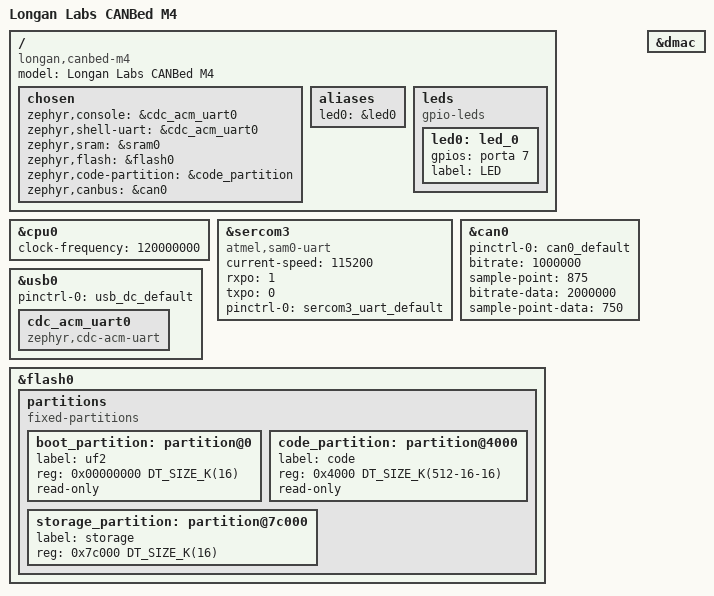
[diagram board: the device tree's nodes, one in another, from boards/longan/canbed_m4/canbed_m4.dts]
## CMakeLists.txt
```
# SPDX-License-Identifier: Apache-2.0
cmake_minimum_required(VERSION 3.20.0)

# The CMSIS device header for the ATSAME51G19A is not shipped by hal_atmel;
# soc.h (patched, see zephyr/patches/) includes <same51g19a.h> from here.
list(APPEND BOARD_ROOT ${CMAKE_CURRENT_SOURCE_DIR})

find_package(Zephyr REQUIRED HINTS $ENV{ZEPHYR_BASE})
project(canbed_m4_can_loopback)

zephyr_include_directories(include)

target_sources(app PRIVATE
  src/main.c
  src/dm/dm_motor.c
  src/dm/dm_motor_pack.c
  src/dm/dm_shell.c
)
target_include_directories(app PRIVATE src/dm)

# Keeps big app buffers behind the CAN message RAM (see the file).
zephyr_linker_sources(NOINIT linker/dm_trace.ld)
```

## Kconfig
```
# SPDX-License-Identifier: Apache-2.0

module = DM_MOTOR
module-str = dm_motor
source "subsys/logging/Kconfig.template.log_config"

source "Kconfig.zephyr"
```

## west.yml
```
# West manifest: Zephyr 4.4 plus only the modules this board needs.
manifest:
  remotes:
    - name: zephyrproject-rtos
      url-base: https://github.com/zephyrproject-rtos
  projects:
    - name: zephyr
      remote: zephyrproject-rtos
      revision: v4.4.0
      import:
        name-allowlist:
          - cmsis
          - cmsis_6
          - hal_atmel
  self:
    path: app
```

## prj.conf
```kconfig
CONFIG_CAN=y
CONFIG_CAN_FD_MODE=y
CONFIG_CAN_LOG_LEVEL_INF=y

CONFIG_LOG=y
CONFIG_LOG_MODE_IMMEDIATE=y
CONFIG_PRINTK=y

CONFIG_SHELL=y
CONFIG_CAN_SHELL=y
CONFIG_DEVICE_SHELL=y
CONFIG_KERNEL_SHELL=y

CONFIG_MAIN_STACK_SIZE=2048

# Shell needs float printing and a bit more stack for the dm commands.
CONFIG_CBPRINTF_FP_SUPPORT=y
CONFIG_SHELL_STACK_SIZE=3072
CONFIG_DM_MOTOR_LOG_LEVEL_INF=y

# strtof for the shell commands (minimal libc lacks it)
CONFIG_NEWLIB_LIBC=y
CONFIG_NEWLIB_LIBC_NANO=y

# The motor loops run on the system work queue at 1 kHz; printk with floats needs room.
CONFIG_SYSTEM_WORKQUEUE_STACK_SIZE=2048
```

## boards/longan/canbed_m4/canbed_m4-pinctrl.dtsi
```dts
/*
 * Pin multiplexing for the Longan Labs CANBed M4 (ATSAME51G19A, QFN48).
 * SPDX-License-Identifier: Apache-2.0
 */

#include <dt-bindings/pinctrl/same51g-pinctrl.h>

&pinctrl {
	/* Serial1 on the Grove connector / 2x9 header: PA17 TX, PA16 RX */
	sercom3_uart_default: sercom3_uart_default {
		group1 {
			pinmux = <PA17D_SERCOM3_PAD0>,
				 <PA16D_SERCOM3_PAD1>;
		};
	};

	/* I2C on the Grove connector: PA12 SDA, PA13 SCL */
	sercom2_i2c_default: sercom2_i2c_default {
		group1 {
			pinmux = <PA12C_SERCOM2_PAD0>,
				 <PA13C_SERCOM2_PAD1>;
		};
	};

	/* SPI header J8: PA00 MOSI, PA01 SCK, PB23 MISO */
	sercom1_spi_default: sercom1_spi_default {
		group1 {
			pinmux = <PA0D_SERCOM1_PAD0>,
				 <PA1D_SERCOM1_PAD1>,
				 <PB23C_SERCOM1_PAD3>;
		};
	};

	/* CAN0 to the MCP2542FD transceiver (STBY tied low) */
	can0_default: can0_default {
		group1 {
			pinmux = <PA22I_CAN0_TX>,
				 <PA23I_CAN0_RX>;
		};
	};

	usb_dc_default: usb_dc_default {
		group1 {
			pinmux = <PA25H_USB_DP>,
				 <PA24H_USB_DM>;
		};
	};
};
```

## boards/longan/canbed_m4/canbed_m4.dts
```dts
/*
 * Longan Labs CANBed M4: ATSAME51G19A (Cortex-M4F, 512 KiB flash, 192 KiB RAM)
 * with an MCP2542FD CAN FD transceiver, USB, and a 16 KiB UF2 bootloader.
 *
 * SPDX-License-Identifier: Apache-2.0
 */

/dts-v1/;
#include <atmel/same5xx19.dtsi>
#include <zephyr/dt-bindings/gpio/gpio.h>
#include "canbed_m4-pinctrl.dtsi"

/ {
	model = "Longan Labs CANBed M4";
	compatible = "longan,canbed-m4";

	chosen {
		zephyr,console = &cdc_acm_uart0;
		zephyr,shell-uart = &cdc_acm_uart0;
		zephyr,sram = &sram0;
		zephyr,flash = &flash0;
		zephyr,code-partition = &code_partition;
		zephyr,canbus = &can0;
	};

	aliases {
		led0 = &led0;
	};

	leds {
		compatible = "gpio-leds";

		/* D5, blue, active high (Arduino D13) */
		led0: led_0 {
			gpios = <&porta 7 GPIO_ACTIVE_HIGH>;
			label = "LED";
		};
	};
};

&cpu0 {
	clock-frequency = <120000000>;
};

/* Serial1 (Grove J11 / header J12) */
&sercom3 {
	status = "okay";
	compatible = "atmel,sam0-uart";
	current-speed = <115200>;
	rxpo = <1>;
	txpo = <0>;
	pinctrl-0 = <&sercom3_uart_default>;
	pinctrl-names = "default";
};

&can0 {
	status = "okay";
	pinctrl-0 = <&can0_default>;
	pinctrl-names = "default";
	bitrate = <1000000>;
	sample-point = <875>;
	bitrate-data = <2000000>;
	sample-point-data = <750>;
};

zephyr_udc0: &usb0 {
	status = "okay";
	pinctrl-0 = <&usb_dc_default>;
	pinctrl-names = "default";

	cdc_acm_uart0: cdc_acm_uart0 {
		compatible = "zephyr,cdc-acm-uart";
	};
};

&dmac {
	status = "okay";
};

&flash0 {
	partitions {
		compatible = "fixed-partitions";
		#address-cells = <1>;
		#size-cells = <1>;

		boot_partition: partition@0 {
			label = "uf2";
			reg = <0x00000000 DT_SIZE_K(16)>;
			read-only;
		};

		code_partition: partition@4000 {
			label = "code";
			reg = <0x4000 DT_SIZE_K(512-16-16)>;
			read-only;
		};

		/* last 16 KiB free for NVS/LittleFS if wanted */
		storage_partition: partition@7c000 {
			label = "storage";
			reg = <0x7c000 DT_SIZE_K(16)>;
		};
	};
};
```

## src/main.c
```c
/*
 * CANBed M4 CAN loopback self-test.
 *
 * Puts CAN0 into internal loopback (frames are transmitted and received by the
 * same controller without reaching the bus pins), sends a classic
 * frame and a 64-byte CAN FD frame with bit-rate switching, and checks that
 * both come back intact.  Results go to the USB CDC console, where the
 * Zephyr shell (`can ...` commands) stays available afterwards.
 *
 * SPDX-License-Identifier: Apache-2.0
 */

#include <string.h>

#include <zephyr/device.h>
#include <zephyr/drivers/can.h>
#include <zephyr/drivers/gpio.h>
#include <zephyr/drivers/uart.h>
#include <zephyr/shell/shell.h>
#include <zephyr/kernel.h>
#include <zephyr/logging/log.h>
#include <zephyr/version.h>
#include <zephyr/sys/byteorder.h>

#include "dm_motor.h"

LOG_MODULE_REGISTER(loopback, LOG_LEVEL_INF);

static const struct device *const can_dev = DEVICE_DT_GET(DT_CHOSEN(zephyr_canbus));
static const struct gpio_dt_spec led = GPIO_DT_SPEC_GET(DT_ALIAS(led0), gpios);

CAN_MSGQ_DEFINE(rx_msgq, 8);

#define TEST_ID_CLASSIC 0x123
#define TEST_ID_FD      0x1ABCDEF

static int add_filters(void)
{
	const struct can_filter classic = {
		.id = TEST_ID_CLASSIC,
		.mask = CAN_STD_ID_MASK,
		.flags = 0,
	};
	const struct can_filter fd = {
		.id = TEST_ID_FD,
		.mask = CAN_EXT_ID_MASK,
		.flags = CAN_FILTER_IDE,
	};
	int ret;

	ret = can_add_rx_filter_msgq(can_dev, &rx_msgq, &classic);
	if (ret < 0) {
		LOG_ERR("standard filter: %d", ret);
		return ret;
	}
	ret = can_add_rx_filter_msgq(can_dev, &rx_msgq, &fd);
	if (ret < 0) {
		LOG_ERR("extended filter: %d", ret);
		return ret;
	}
	return 0;
}

static void tx_done(const struct device *dev, int error, void *user_data)
{
	if (error != 0) {
		LOG_ERR("tx callback error %d", error);
	}
}

/* Send one frame and wait for it to come back through the loopback. */
static int roundtrip(const struct can_frame *tx, const char *name)
{
	struct can_frame rx;
	int ret;

	k_msgq_purge(&rx_msgq);

	ret = can_send(can_dev, tx, K_MSEC(200), tx_done, NULL);
	if (ret != 0) {
		LOG_ERR("%s: can_send failed: %d", name, ret);
		return ret;
	}

	ret = k_msgq_get(&rx_msgq, &rx, K_MSEC(200));
	if (ret != 0) {
		LOG_ERR("%s: nothing received (%d)", name, ret);
		return -ETIMEDOUT;
	}

	size_t len = can_dlc_to_bytes(tx->dlc);

	if (rx.id != tx->id || rx.dlc != tx->dlc ||
	    (rx.flags & (CAN_FRAME_IDE | CAN_FRAME_FDF | CAN_FRAME_BRS)) !=
		    (tx->flags & (CAN_FRAME_IDE | CAN_FRAME_FDF | CAN_FRAME_BRS)) ||
	    memcmp(rx.data, tx->data, len) != 0) {
		LOG_ERR("%s: mismatch: id 0x%x/0x%x dlc %u/%u flags 0x%x/0x%x", name,
			rx.id, tx->id, rx.dlc, tx->dlc, rx.flags, tx->flags);
		LOG_HEXDUMP_ERR(rx.data, len, "rx");
		return -EIO;
	}

	LOG_INF("%s: OK (id 0x%x, %u bytes%s)", name, rx.id, (unsigned int)len,
		(rx.flags & CAN_FRAME_BRS) ? ", FD+BRS" : "");
	return 0;
}

static int run_selftest(void)
{
	struct can_frame frame;
	int failures = 0;

	/* Classic CAN 2.0A, 8 bytes */
	memset(&frame, 0, sizeof(frame));
	frame.id = TEST_ID_CLASSIC;
	frame.dlc = 8;
	for (int i = 0; i < 8; i++) {
		frame.data[i] = 0xA0 + i;
	}
	failures += (roundtrip(&frame, "classic 2.0A") != 0);

	/* CAN FD, extended ID, 64 bytes, bit-rate switch to the data bitrate */
	memset(&frame, 0, sizeof(frame));
	frame.id = TEST_ID_FD;
	frame.flags = CAN_FRAME_IDE | CAN_FRAME_FDF | CAN_FRAME_BRS;
	frame.dlc = can_bytes_to_dlc(64);
	for (int i = 0; i < 64; i++) {
		frame.data[i] = (uint8_t)(i * 3);
	}
	failures += (roundtrip(&frame, "CAN FD 64B") != 0);

	return failures;
}

static int cmd_loopback(const struct shell *sh, size_t argc, char **argv)
{
	ARG_UNUSED(argc);
	ARG_UNUSED(argv);

	int failures = run_selftest();

	shell_print(sh, "CAN loopback self-test: %s", failures ? "FAILED" : "PASSED");
	return failures ? -EIO : 0;
}
SHELL_CMD_REGISTER(loopback, NULL, "Run the CAN loopback self-test again", cmd_loopback);

/* Give the host a moment to open the CDC ACM console so the boot-time test
 * output is not lost; continue regardless after the timeout.
 */
static void wait_for_console(void)
{
	const struct device *console = DEVICE_DT_GET(DT_CHOSEN(zephyr_console));
	uint32_t dtr = 0;

	for (int i = 0; i < 150 && dtr == 0; i++) {
		if (uart_line_ctrl_get(console, UART_LINE_CTRL_DTR, &dtr) != 0) {
			break;
		}
		k_sleep(K_MSEC(100));
	}
	k_sleep(K_MSEC(200));
}

int main(void)
{
	struct can_bus_err_cnt err;
	enum can_state state;
	can_mode_t caps;
	int ret;

	if (gpio_is_ready_dt(&led)) {
		gpio_pin_configure_dt(&led, GPIO_OUTPUT_INACTIVE);
	}

	wait_for_console();
	printk("\nCANBed M4 (ATSAME51G19A) Zephyr %s, board %s\n", KERNEL_VERSION_STRING, CONFIG_BOARD);

	if (!device_is_ready(can_dev)) {
		LOG_ERR("CAN device %s not ready", can_dev->name);
		return 0;
	}

	ret = can_get_capabilities(can_dev, &caps);
	LOG_INF("%s capabilities: 0x%x (loopback %s, FD %s)", can_dev->name, caps,
		(caps & CAN_MODE_LOOPBACK) ? "yes" : "no", (caps & CAN_MODE_FD) ? "yes" : "no");

	ret = add_filters();
	if (ret < 0) {
		return 0;
	}

	/*
	 * Loopback plus listen-only is the MCAN's internal loopback: frames are
	 * received by the controller itself but not driven onto the pins.  Plain
	 * loopback does drive the bus, and a 64-byte FD frame at the data rate on
	 * a bus with classic-CAN motors gets error-flagged into bus-off.
	 */
	ret = can_set_mode(can_dev, CAN_MODE_LOOPBACK | CAN_MODE_LISTENONLY | CAN_MODE_FD);
	if (ret != 0) {
		LOG_ERR("can_set_mode: %d", ret);
		return 0;
	}

	ret = can_start(can_dev);
	if (ret != 0) {
		LOG_ERR("can_start: %d", ret);
		return 0;
	}

	uint32_t rate = 0, rate_data = 0;

	can_get_core_clock(can_dev, &rate);
	LOG_INF("CAN core clock %u Hz, mode loopback+FD, %u kbit/s nominal", rate, 1000U);
	ARG_UNUSED(rate_data);

	int failures = run_selftest();

	can_get_state(can_dev, &state, &err);
	LOG_INF("bus state %d, tx errors %u, rx errors %u", state, err.tx_err_cnt, err.rx_err_cnt);

	if (failures == 0) {
		printk("\n*** CAN LOOPBACK SELF-TEST PASSED ***\n\n");
	} else {
		printk("\n*** CAN LOOPBACK SELF-TEST FAILED (%d) ***\n\n", failures);
	}

	/* Leave loopback: normal CAN 2.0 mode for the motor bus (dm bus ... changes it). */
	ret = dm_bus_configure(can_dev, false, false);
	if (ret) {
		LOG_ERR("switching to normal mode failed: %d", ret);
	} else {
		LOG_INF("CAN0 in normal mode, 1 Mbit/s; use 'dm' commands for the motor");
	}

	/* Heartbeat LED: fast blink on pass, slow on fail. */
	while (1) {
		gpio_pin_toggle_dt(&led);
		k_sleep(K_MSEC(failures ? 1000 : 200));
	}
	return 0;
}
```
